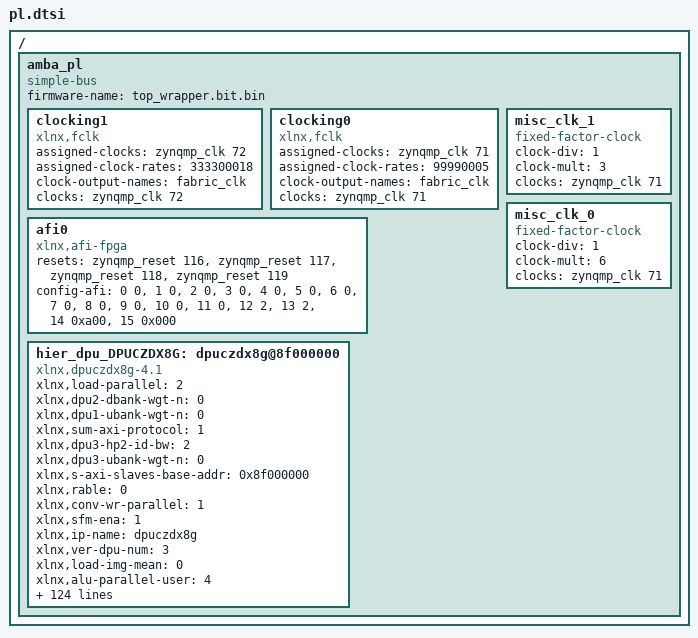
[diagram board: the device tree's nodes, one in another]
/ {
	amba_pl: amba_pl {
		ranges;
		compatible = "simple-bus";
		#address-cells = <2>;
		#size-cells = <2>;
		firmware-name = "top_wrapper.bit.bin";
		clocking1: clocking1 {
			compatible = "xlnx,fclk";
			status = "okay";
			assigned-clocks = <&zynqmp_clk 72>;
			assigned-clock-rates = <333300018>;
			#clock-cells = <0>;
			clock-output-names = "fabric_clk";
			clocks = <&zynqmp_clk 72>;
		};
		clocking0: clocking0 {
			compatible = "xlnx,fclk";
			status = "okay";
			assigned-clocks = <&zynqmp_clk 71>;
			assigned-clock-rates = <99990005>;
			#clock-cells = <0>;
			clock-output-names = "fabric_clk";
			clocks = <&zynqmp_clk 71>;
		};
		afi0: afi0 {
			status = "okay";
			compatible = "xlnx,afi-fpga";
			resets = <&zynqmp_reset 116>, <&zynqmp_reset 117>, <&zynqmp_reset 118>, <&zynqmp_reset 119>;
			config-afi = < 0 0>, <1 0>, <2 0>, <3 0>, <4 0>, <5 0>, <6 0>, <7 0>, <8 0>, <9 0>, <10 0>, <11 0>, <12 2>, <13 2>, <14 0xa00>, <15 0x000>;
		};
		misc_clk_1: misc_clk_1 {
			clock-div = <1>;
			compatible = "fixed-factor-clock";
			clock-mult = <3>;
			clocks = <&zynqmp_clk 71>;
			#clock-cells = <0>;
		};
		misc_clk_0: misc_clk_0 {
			clock-div = <1>;
			compatible = "fixed-factor-clock";
			clock-mult = <6>;
			clocks = <&zynqmp_clk 71>;
			#clock-cells = <0>;
		};
		hier_dpu_DPUCZDX8G: dpuczdx8g@8f000000 {
			xlnx,load-parallel = <2>;
			xlnx,dpu2-dbank-wgt-n = <0>;
			xlnx,dpu1-ubank-wgt-n = <0>;
			xlnx,sum-axi-protocol = <1>;
			xlnx,dpu3-hp2-id-bw = <2>;
			xlnx,dpu3-ubank-wgt-n = <0>;
			xlnx,s-axi-slaves-base-addr = <0x8f000000>;
			xlnx,rable = <0>;
			xlnx,conv-wr-parallel = <1>;
			xlnx,sfm-ena = <1>;
			xlnx,ip-name = "dpuczdx8g";
			xlnx,ver-dpu-num = <3>;
			xlnx,load-img-mean = <0>;
			xlnx,alu-parallel-user = <4>;
			reg = <0x0 0x8f000000 0x0 0x1000000>;
			xlnx,bank-bias = <1>;
			xlnx,sum-s-axi-data-bw = <32>;
			xlnx,hp1-id-bw = <2>;
			xlnx,dnndk-print = "Number , of , DPU , Cores:3;Arch , of , DPU:B4096;RAM , Usage:Low;Channel , Augmentation:Enabled;DepthWiseConv:Enabled;AveragePool:Enabled;Conv , ReLU , Type:ReLU , + , LeakyReLU , + , ReLU6;Number , of , SFM , cores:1;S-AXI , Clock , Mode:Independent;dpu_2x , Clock , Gating:Enabled;DSP48 , Maximal , Cascade , Length:4;DSP48 , Usage:High;Ultra-RAM , Use , per , DPU:0;Enable , timestamp , auto-update:Enabled;Target , Version:1.4.1;AXI , Protocol:AXI4;S-AXI , Data , Width:32;M-AXI , GP , Data , Width:32;M-AXI , HP , Data , Width , (DPU):128;M-AXI , HP , Data , Width , (SFM):128;M-AXI , ID , Width:2;DSP , Slice , Count:2144;Ultra-RAM , Count:0.0;Block-RAM , Count:769.0";
			xlnx,time-day = <9>;
			xlnx,sum-sfm-hp-data-bw = <128>;
			xlnx,dbank-wgt-n = <0>;
			xlnx,uram-n-user = <0>;
			xlnx,ram-depth-img = <3>;
			xlnx,dpu1-dbank-img-n = <0>;
			xlnx,dpu3-dbank-bias = <0>;
			xlnx,dpu2-ubank-bias = <0>;
			xlnx,sum-gp-data-bw = <32>;
			xlnx,dpu3-dbank-img-n = <0>;
			xlnx,dpu2-ubank-img-n = <0>;
			xlnx,sys-ip-ver = <0x41>;
			interrupt-names = "dpu0_interrupt" , "dpu1_interrupt" , "dpu2_interrupt" , "sfm_interrupt";
			xlnx,dpu2-hp0-id-bw = <2>;
			xlnx,ram-depth-wgt = <3>;
			xlnx,ubank-img-n-user = <0>;
			xlnx,time-month = <5>;
			xlnx,dpu3-hp1-id-bw = <2>;
			compatible = "xlnx,dpuczdx8g-4.1";
			xlnx,dpu1-hp3-id-bw = <2>;
			xlnx,sum-ver-target = "1.4.1";
			xlnx,bbank-img-n = <16>;
			xlnx,git-commit-id = <0x7d32c41>;
			xlnx,conv-dsp-casc-max = <4>;
			xlnx,ubank-bias = <0>;
			xlnx,arch-ocp = <16>;
			interrupt-parent = <&imux>;
			xlnx,ubank-img-n = <0>;
			xlnx,git-commit-time = <2023022121>;
			xlnx,sum-hp-data-bw = <128>;
			xlnx,sum-bram-n = <769>;
			xlnx,conv-dsp-num = <640>;
			xlnx,hp0-id-bw = <2>;
			xlnx,arch-hp-bw = <3>;
			xlnx,conv-relu6 = <1>;
			xlnx,ver-chip-part = <3>;
			xlnx,s-axi-id-bw = <16>;
			xlnx,dpu1-dbank-bias = <0>;
			xlnx,elew-mult-en = <1>;
			xlnx,alu-parallel = <4>;
			xlnx,conv-dsp-accu-ena = <1>;
			xlnx,ver-ip-rev = <0x0>;
			xlnx,dsp48-ver = "DSP48E2";
			xlnx,alu-leakyrelu = <0>;
			xlnx,git-commit-user = "jasonjia";
			status = "okay";
			xlnx,sys-regmap-size = <12>;
			xlnx,dpu3-hp0-id-bw = <2>;
			xlnx,name = "hier_dpu_DPUCZDX8G";
			xlnx,bank-img-n = <16>;
			xlnx,dpu1-dbank-wgt-n = <0>;
			xlnx,dpu1-hp2-id-bw = <2>;
			interrupts = < 0 89 4 0 90 4 0 91 4 0 92 4 >;
			xlnx,sum-uram-n = <0>;
			xlnx,dpu3-dbank-wgt-n = <0>;
			xlnx,dpu2-ubank-wgt-n = <0>;
			xlnx,dpu2-hp3-id-bw = <2>;
			xlnx,arch-pp = <8>;
			xlnx,save-argmax-ena = <1>;
			xlnx,ram-depth-bias = <3>;
			xlnx,dpu3-ubank-bias = <0>;
			xlnx,arch = <4096>;
			xlnx,sfm-hp-data-bw = <128>;
			xlnx,bbank-wgt-n = <17>;
			clocks = <&misc_clk_0>, <&misc_clk_0>, <&misc_clk_0>, <&misc_clk_1>, <&zynqmp_clk 71>;
			xlnx,ubank-bias-user = <0>;
			xlnx,s-axi-freq-mhz = <100>;
			xlnx,time-hour = <15>;
			xlnx,bbank-bias = <1>;
			xlnx,ubank-wgt-n = <0>;
			xlnx,hp3-id-bw = <2>;
			xlnx,arch-data-bw = <1>;
			xlnx,sys-ip-type = <1>;
			xlnx,edk-iptype = "PERIPHERAL";
			xlnx,dwcv-ena = <1>;
			xlnx,dpu1-ubank-img-n = <0>;
			xlnx,dpu2-dbank-img-n = <0>;
			xlnx,s-axi-awrlen-bw = <8>;
			xlnx,dpu1-gp-id-bw = <2>;
			clock-names = "dpu1_2x_clk" , "dpu2_2x_clk" , "dpu_2x_clk" , "m_axi_dpu_aclk" , "s_axi_aclk";
			xlnx,ubank-wgt-n-user = <0>;
			xlnx,sfm-dsp-num = <14>;
			xlnx,dpu3-ubank-img-n = <0>;
			xlnx,arch-icp = <16>;
			xlnx,save-dsp-num = <1>;
			xlnx,ram-depth-mean = <1>;
			xlnx,dpu1-hp1-id-bw = <2>;
			xlnx,ver-target = <0x141>;
			xlnx,load-dsp-num = <1>;
			xlnx,pool-average = <1>;
			xlnx,dpu2-hp2-id-bw = <2>;
			xlnx,sfm-hp0-id-bw = <2>;
			xlnx,arch-img-bkgrp = <2>;
			xlnx,s-axi-clk-independent = <1>;
			xlnx,misc-wr-parallel = <1>;
			xlnx,dpu3-hp3-id-bw = <2>;
			xlnx,dpu1-ubank-bias = <0>;
			xlnx,dpu2-dbank-bias = <0>;
			xlnx,time-year = <25>;
			xlnx,hp-data-bw = <128>;
			xlnx,dbank-img-n = <0>;
			xlnx,sum-dsp-num = <2144>;
			xlnx,bank-wgt-n = <17>;
			xlnx,load-augm = <1>;
			xlnx,dpu2-gp-id-bw = <2>;
			xlnx,time-quarter = <2>;
			xlnx,save-parallel = <2>;
			xlnx,conv-leakyrelu = <1>;
			xlnx,sys-regmap-ver = <0x1>;
			xlnx,hp2-id-bw = <2>;
			xlnx,clk-gating-ena = <1>;
			xlnx,alu-dsp-num = <68>;
			xlnx,dbank-bias = <0>;
			xlnx,timestamp-ena = <1>;
			xlnx,conv-relu-addon = <3>;
			xlnx,gp-id-bw = <2>;
			xlnx,elew-parallel = <4>;
			xlnx,dpu1-hp0-id-bw = <2>;
			xlnx,dpu3-gp-id-bw = <2>;
			xlnx,dpu2-hp1-id-bw = <2>;
			xlnx,axi-protocol = <1>;
		};
	};
};
